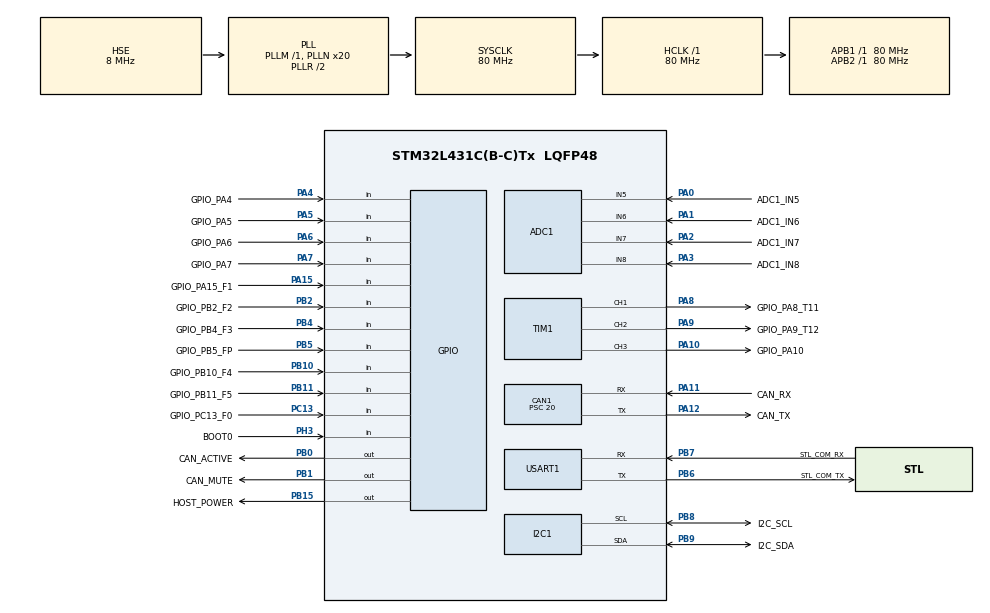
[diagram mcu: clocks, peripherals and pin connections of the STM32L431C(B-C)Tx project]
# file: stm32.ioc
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ADC1.Channel-0\#ChannelRegularConversion=ADC_CHANNEL_5
ADC1.NbrOfConversionFlag=1
ADC1.OffsetNumber-0\#ChannelRegularConversion=ADC_OFFSET_NONE
ADC1.Rank-0\#ChannelRegularConversion=1
ADC1.SamplingTime-0\#ChannelRegularConversion=ADC_SAMPLETIME_2CYCLES_5
ADC1.master=1
CAN1.ABOM=ENABLE
CAN1.BS1=CAN_BS1_13TQ
CAN1.BS2=CAN_BS2_2TQ
CAN1.CalculateBaudRate=250000
CAN1.CalculateTimeBit=4000
CAN1.CalculateTimeQuantum=250.0
CAN1.NART=ENABLE
CAN1.Prescaler=20
CAN1.TXFP=ENABLE
I2C1.Timing=0x10D19CE4
Mcu.Family=STM32L4
Mcu.Name=STM32L431C(B-C)Tx
Mcu.Package=LQFP48
NVIC.CAN1_RX0_IRQn=true\:0\:0\:false\:false\:true\:true\:true\:true
NVIC.CAN1_SCE_IRQn=true\:0\:0\:false\:false\:true\:true\:true\:true
NVIC.CAN1_TX_IRQn=true\:0\:0\:false\:false\:true\:true\:true\:true
NVIC.PriorityGroup=NVIC_PRIORITYGROUP_4
PA0.GPIO_Label=ADC1_IN5
PA0.Signal=ADCx_IN5
PA1.GPIO_Label=ADC1_IN6
PA1.Signal=ADCx_IN6
PA10.GPIO_Label=GPIO_PA10
PA10.Signal=S_TIM1_CH3
PA11.GPIO_Label=CAN_RX
PA11.Mode=CAN_Activate
PA11.Signal=CAN1_RX
PA12.GPIO_Label=CAN_TX
PA12.Mode=CAN_Activate
PA12.Signal=CAN1_TX
PA13\ (JTMS-SWDIO).GPIO_Label=SWDIO
PA13\ (JTMS-SWDIO).Mode=Trace_Asynchronous_SW
PA13\ (JTMS-SWDIO).Signal=SYS_JTMS-SWDIO
PA14\ (JTCK-SWCLK).GPIO_Label=SWCLK
PA14\ (JTCK-SWCLK).Mode=Trace_Asynchronous_SW
PA14\ (JTCK-SWCLK).Signal=SYS_JTCK-SWCLK
PA15\ (JTDI).GPIO_Label=GPIO_PA15_F1
PA15\ (JTDI).Signal=GPIO_Input
PA2.GPIO_Label=ADC1_IN7
PA2.Signal=ADCx_IN7
PA3.GPIO_Label=ADC1_IN8
PA3.Signal=ADCx_IN8
PA4.GPIO_Label=GPIO_PA4
PA4.Signal=GPIO_Input
PA5.GPIO_Label=GPIO_PA5
PA5.Signal=GPIO_Input
PA6.GPIO_Label=GPIO_PA6
PA6.Signal=GPIO_Input
PA7.GPIO_Label=GPIO_PA7
PA7.Signal=GPIO_Input
PA8.GPIO_Label=GPIO_PA8_T11
PA8.Signal=S_TIM1_CH1
PA9.GPIO_Label=GPIO_PA9_T12
PA9.Signal=S_TIM1_CH2
PB0.GPIO_Label=CAN_ACTIVE
PB0.PinState=GPIO_PIN_SET
PB0.Signal=GPIO_Output
PB1.GPIO_Label=CAN_MUTE
PB1.Signal=GPIO_Output
PB10.GPIO_Label=GPIO_PB10_F4
PB10.Signal=GPIO_Input
PB11.GPIO_Label=GPIO_PB11_F5
PB11.Signal=GPIO_Input
PB15.GPIO_Label=HOST_POWER
PB15.Signal=GPIO_Output
PB2.GPIO_Label=GPIO_PB2_F2
PB2.Signal=GPIO_Input
PB3\ (JTDO-TRACESWO).GPIO_Label=TRACESWO
PB3\ (JTDO-TRACESWO).Mode=Trace_Asynchronous_SW
PB3\ (JTDO-TRACESWO).Signal=SYS_JTDO-SWO
PB4\ (NJTRST).GPIO_Label=GPIO_PB4_F3
PB4\ (NJTRST).Signal=GPIO_Input
PB5.GPIO_Label=GPIO_PB5_FP
PB5.Signal=GPIO_Input
PB6.GPIO_Label=STL_COM_TX
PB6.Mode=Asynchronous
PB6.Signal=USART1_TX
PB7.GPIO_Label=STL_COM_RX
PB7.Mode=Asynchronous
PB7.Signal=USART1_RX
PB8.GPIO_Label=I2C_SCL
PB8.Mode=I2C
PB8.Signal=I2C1_SCL
PB9.GPIO_Label=I2C_SDA
PB9.Mode=I2C
PB9.Signal=I2C1_SDA
PC13.GPIO_Label=GPIO_PC13_F0
PC13.Signal=GPIO_Input
PC14-OSC32_IN\ (PC14).Mode=LSE-External-Oscillator
PC14-OSC32_IN\ (PC14).Signal=RCC_OSC32_IN
PC15-OSC32_OUT\ (PC15).Mode=LSE-External-Oscillator
PC15-OSC32_OUT\ (PC15).Signal=RCC_OSC32_OUT
PH0-OSC_IN\ (PH0).Mode=HSE-External-Oscillator
PH0-OSC_IN\ (PH0).Signal=RCC_OSC_IN
PH1-OSC_OUT\ (PH1).Mode=HSE-External-Oscillator
PH1-OSC_OUT\ (PH1).Signal=RCC_OSC_OUT
PH3-BOOT0.GPIO_Label=BOOT0
PH3-BOOT0.Signal=GPIO_Input
ProjectManager.HeapSize=0x200
ProjectManager.StackSize=0x400
ProjectManager.TargetToolchain=CMake
RCC.ADCFreq_Value=32000000
RCC.AHBFreq_Value=80000000
RCC.APB1Freq_Value=80000000
RCC.APB1TimFreq_Value=80000000
RCC.APB2Freq_Value=80000000
RCC.APB2TimFreq_Value=80000000
RCC.CortexFreq_Value=80000000
RCC.HCLKFreq_Value=80000000
RCC.HSI48_VALUE=48000000
RCC.HSI_VALUE=16000000
RCC.MSI_VALUE=4000000
RCC.PLLN=20
RCC.PLLSourceVirtual=RCC_PLLSOURCE_HSE
RCC.RTCClockSelection=RCC_RTCCLKSOURCE_LSE
RCC.SYSCLKFreq_VALUE=80000000
RCC.SYSCLKSource=RCC_SYSCLKSOURCE_PLLCLK
RCC.VCOOutputFreq_Value=160000000
SH.ADCx_IN5.0=ADC1_IN5,IN5-Single-Ended
SH.ADCx_IN6.0=ADC1_IN6,IN6-Single-Ended
SH.ADCx_IN7.0=ADC1_IN7,IN7-Single-Ended
SH.ADCx_IN8.0=ADC1_IN8,IN8-Single-Ended
SH.S_TIM1_CH1.0=TIM1_CH1,PWM Generation1 CH1
SH.S_TIM1_CH2.0=TIM1_CH2,PWM Generation2 CH2
SH.S_TIM1_CH3.0=TIM1_CH3,PWM Generation3 CH3
TIM1.Channel-PWM\ Generation1\ CH1=TIM_CHANNEL_1
TIM1.Channel-PWM\ Generation2\ CH2=TIM_CHANNEL_2
TIM1.Channel-PWM\ Generation3\ CH3=TIM_CHANNEL_3
TIM1.OCPolarity_1=TIM_OCPOLARITY_LOW
TIM1.OCPolarity_2=TIM_OCPOLARITY_LOW
USART1.VirtualMode-Asynchronous=VM_ASYNC
VP_ADC1_Vref_Input.Mode=IN-Vrefint
VP_RTC_VS_RTC_Activate.Mode=RTC_Enabled
board=custom

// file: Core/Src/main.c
/* USER CODE BEGIN Header */
/**
  ******************************************************************************
  * @file           : main.c
  * @brief          : Main program body
  ******************************************************************************
  * @attention
  *
  * Copyright (c) 2026 STMicroelectronics.
  * All rights reserved.
  *
  * This software is licensed under terms that can be found in the LICENSE file
  * in the root directory of this software component.
  * If no LICENSE file comes with this software, it is provided AS-IS.
  *
  ******************************************************************************
  */
/* USER CODE END Header */
#include "main.h"

/* USER CODE BEGIN Includes */
#include "can_mcu/fatal.h"
#include "lab_test_01/app.h"

/* USER CODE END Includes */

ADC_HandleTypeDef hadc1;

CAN_HandleTypeDef hcan1;

I2C_HandleTypeDef hi2c1;

RTC_HandleTypeDef hrtc;

TIM_HandleTypeDef htim1;

UART_HandleTypeDef huart1;

void SystemClock_Config(void);
static void MX_GPIO_Init(void);
static void MX_CAN1_Init(void);
static void MX_I2C1_Init(void);
static void MX_TIM1_Init(void);
static void MX_USART1_UART_Init(void);
static void MX_ADC1_Init(void);
static void MX_RTC_Init(void);

int main(void)
{

  /* MCU Configuration--------------------------------------------------------*/

  /* Reset of all peripherals, Initializes the Flash interface and the Systick. */
  HAL_Init();

  /* Configure the system clock */
  SystemClock_Config();

  /* Initialize all configured peripherals */
  MX_GPIO_Init();
  MX_CAN1_Init();
  MX_I2C1_Init();
  MX_TIM1_Init();
  MX_USART1_UART_Init();
  MX_ADC1_Init();
  MX_RTC_Init();
  /* USER CODE BEGIN 2 */
  lab_test_01_app_init();

  /* USER CODE END 2 */

  /* Infinite loop */
  while (1)
  {

    /* USER CODE BEGIN 3 */
    lab_test_01_app_run();
  }
  /* USER CODE END 3 */
}

void SystemClock_Config(void)
{
  RCC_OscInitTypeDef RCC_OscInitStruct = {0};
  RCC_ClkInitTypeDef RCC_ClkInitStruct = {0};

  /** Configure the main internal regulator output voltage
  */
  if (HAL_PWREx_ControlVoltageScaling(PWR_REGULATOR_VOLTAGE_SCALE1) != HAL_OK)
  {
    Error_Handler();
  }

  /** Configure LSE Drive Capability
  */
  HAL_PWR_EnableBkUpAccess();
  __HAL_RCC_LSEDRIVE_CONFIG(RCC_LSEDRIVE_LOW);

  /** Initializes the RCC Oscillators according to the specified parameters
  * in the RCC_OscInitTypeDef structure.
  */
  RCC_OscInitStruct.OscillatorType = RCC_OSCILLATORTYPE_HSE|RCC_OSCILLATORTYPE_LSE;
  RCC_OscInitStruct.HSEState = RCC_HSE_ON;
  RCC_OscInitStruct.LSEState = RCC_LSE_ON;
  RCC_OscInitStruct.PLL.PLLState = RCC_PLL_ON;
  RCC_OscInitStruct.PLL.PLLSource = RCC_PLLSOURCE_HSE;
  RCC_OscInitStruct.PLL.PLLM = 1;
  RCC_OscInitStruct.PLL.PLLN = 20;
  RCC_OscInitStruct.PLL.PLLP = RCC_PLLP_DIV7;
  RCC_OscInitStruct.PLL.PLLQ = RCC_PLLQ_DIV2;
  RCC_OscInitStruct.PLL.PLLR = RCC_PLLR_DIV2;
  if (HAL_RCC_OscConfig(&RCC_OscInitStruct) != HAL_OK)
  {
    Error_Handler();
  }

  /** Initializes the CPU, AHB and APB buses clocks
  */
  RCC_ClkInitStruct.ClockType = RCC_CLOCKTYPE_HCLK|RCC_CLOCKTYPE_SYSCLK
                              |RCC_CLOCKTYPE_PCLK1|RCC_CLOCKTYPE_PCLK2;
  RCC_ClkInitStruct.SYSCLKSource = RCC_SYSCLKSOURCE_PLLCLK;
  RCC_ClkInitStruct.AHBCLKDivider = RCC_SYSCLK_DIV1;
  RCC_ClkInitStruct.APB1CLKDivider = RCC_HCLK_DIV1;
  RCC_ClkInitStruct.APB2CLKDivider = RCC_HCLK_DIV1;

  if (HAL_RCC_ClockConfig(&RCC_ClkInitStruct, FLASH_LATENCY_4) != HAL_OK)
  {
    Error_Handler();
  }
}

static void MX_ADC1_Init(void)
{

  ADC_ChannelConfTypeDef sConfig = {0};

  /** Common config
  */
  hadc1.Instance = ADC1;
  hadc1.Init.ClockPrescaler = ADC_CLOCK_ASYNC_DIV1;
  hadc1.Init.Resolution = ADC_RESOLUTION_12B;
  hadc1.Init.DataAlign = ADC_DATAALIGN_RIGHT;
  hadc1.Init.ScanConvMode = ADC_SCAN_DISABLE;
  hadc1.Init.EOCSelection = ADC_EOC_SINGLE_CONV;
  hadc1.Init.LowPowerAutoWait = DISABLE;
  hadc1.Init.ContinuousConvMode = DISABLE;
  hadc1.Init.NbrOfConversion = 1;
  hadc1.Init.DiscontinuousConvMode = DISABLE;
  hadc1.Init.ExternalTrigConv = ADC_SOFTWARE_START;
  hadc1.Init.ExternalTrigConvEdge = ADC_EXTERNALTRIGCONVEDGE_NONE;
  hadc1.Init.DMAContinuousRequests = DISABLE;
  hadc1.Init.Overrun = ADC_OVR_DATA_PRESERVED;
  hadc1.Init.OversamplingMode = DISABLE;
  if (HAL_ADC_Init(&hadc1) != HAL_OK)
  {
    Error_Handler();
  }

  /** Configure Regular Channel
  */
  sConfig.Channel = ADC_CHANNEL_5;
  sConfig.Rank = ADC_REGULAR_RANK_1;
  sConfig.SamplingTime = ADC_SAMPLETIME_2CYCLES_5;
  sConfig.SingleDiff = ADC_SINGLE_ENDED;
  sConfig.OffsetNumber = ADC_OFFSET_NONE;
  sConfig.Offset = 0;
  if (HAL_ADC_ConfigChannel(&hadc1, &sConfig) != HAL_OK)
  {
    Error_Handler();
  }

}

static void MX_CAN1_Init(void)
{

  hcan1.Instance = CAN1;
  hcan1.Init.Prescaler = 20;
  hcan1.Init.Mode = CAN_MODE_NORMAL;
  hcan1.Init.SyncJumpWidth = CAN_SJW_1TQ;
  hcan1.Init.TimeSeg1 = CAN_BS1_13TQ;
  hcan1.Init.TimeSeg2 = CAN_BS2_2TQ;
  hcan1.Init.TimeTriggeredMode = DISABLE;
  hcan1.Init.AutoBusOff = ENABLE;
  hcan1.Init.AutoWakeUp = DISABLE;
  hcan1.Init.AutoRetransmission = ENABLE;
  hcan1.Init.ReceiveFifoLocked = DISABLE;
  hcan1.Init.TransmitFifoPriority = ENABLE;
  if (HAL_CAN_Init(&hcan1) != HAL_OK)
  {
    Error_Handler();
  }

}

static void MX_I2C1_Init(void)
{

  hi2c1.Instance = I2C1;
  hi2c1.Init.Timing = 0x10D19CE4;
  hi2c1.Init.OwnAddress1 = 0;
  hi2c1.Init.AddressingMode = I2C_ADDRESSINGMODE_7BIT;
  hi2c1.Init.DualAddressMode = I2C_DUALADDRESS_DISABLE;
  hi2c1.Init.OwnAddress2 = 0;
  hi2c1.Init.OwnAddress2Masks = I2C_OA2_NOMASK;
  hi2c1.Init.GeneralCallMode = I2C_GENERALCALL_DISABLE;
  hi2c1.Init.NoStretchMode = I2C_NOSTRETCH_DISABLE;
  if (HAL_I2C_Init(&hi2c1) != HAL_OK)
  {
    Error_Handler();
  }

  /** Configure Analogue filter
  */
  if (HAL_I2CEx_ConfigAnalogFilter(&hi2c1, I2C_ANALOGFILTER_ENABLE) != HAL_OK)
  {
    Error_Handler();
  }

  /** Configure Digital filter
  */
  if (HAL_I2CEx_ConfigDigitalFilter(&hi2c1, 0) != HAL_OK)
  {
    Error_Handler();
  }

}

static void MX_RTC_Init(void)
{

  /** Initialize RTC Only
  */
  hrtc.Instance = RTC;
  hrtc.Init.HourFormat = RTC_HOURFORMAT_24;
  hrtc.Init.AsynchPrediv = 127;
  hrtc.Init.SynchPrediv = 255;
  hrtc.Init.OutPut = RTC_OUTPUT_DISABLE;
  hrtc.Init.OutPutRemap = RTC_OUTPUT_REMAP_NONE;
  hrtc.Init.OutPutPolarity = RTC_OUTPUT_POLARITY_HIGH;
  hrtc.Init.OutPutType = RTC_OUTPUT_TYPE_OPENDRAIN;
  if (HAL_RTC_Init(&hrtc) != HAL_OK)
  {
    Error_Handler();
  }

}

static void MX_TIM1_Init(void)
{

  TIM_MasterConfigTypeDef sMasterConfig = {0};
  TIM_OC_InitTypeDef sConfigOC = {0};
  TIM_BreakDeadTimeConfigTypeDef sBreakDeadTimeConfig = {0};

  htim1.Instance = TIM1;
  htim1.Init.Prescaler = 0;
  htim1.Init.CounterMode = TIM_COUNTERMODE_UP;
  htim1.Init.Period = 65535;
  htim1.Init.ClockDivision = TIM_CLOCKDIVISION_DIV1;
  htim1.Init.RepetitionCounter = 0;
  htim1.Init.AutoReloadPreload = TIM_AUTORELOAD_PRELOAD_DISABLE;
  if (HAL_TIM_PWM_Init(&htim1) != HAL_OK)
  {
    Error_Handler();
  }
  sMasterConfig.MasterOutputTrigger = TIM_TRGO_RESET;
  sMasterConfig.MasterOutputTrigger2 = TIM_TRGO2_RESET;
  sMasterConfig.MasterSlaveMode = TIM_MASTERSLAVEMODE_DISABLE;
  if (HAL_TIMEx_MasterConfigSynchronization(&htim1, &sMasterConfig) != HAL_OK)
  {
    Error_Handler();
  }
  sConfigOC.OCMode = TIM_OCMODE_PWM1;
  sConfigOC.Pulse = 0;
  sConfigOC.OCPolarity = TIM_OCPOLARITY_LOW;
  sConfigOC.OCNPolarity = TIM_OCNPOLARITY_HIGH;
  sConfigOC.OCFastMode = TIM_OCFAST_DISABLE;
  sConfigOC.OCIdleState = TIM_OCIDLESTATE_RESET;
  sConfigOC.OCNIdleState = TIM_OCNIDLESTATE_RESET;
  if (HAL_TIM_PWM_ConfigChannel(&htim1, &sConfigOC, TIM_CHANNEL_1) != HAL_OK)
  {
    Error_Handler();
  }
  if (HAL_TIM_PWM_ConfigChannel(&htim1, &sConfigOC, TIM_CHANNEL_2) != HAL_OK)
  {
    Error_Handler();
  }
  sConfigOC.OCPolarity = TIM_OCPOLARITY_HIGH;
  if (HAL_TIM_PWM_ConfigChannel(&htim1, &sConfigOC, TIM_CHANNEL_3) != HAL_OK)
  {
    Error_Handler();
  }
  sBreakDeadTimeConfig.OffStateRunMode = TIM_OSSR_DISABLE;
  sBreakDeadTimeConfig.OffStateIDLEMode = TIM_OSSI_DISABLE;
  sBreakDeadTimeConfig.LockLevel = TIM_LOCKLEVEL_OFF;
  sBreakDeadTimeConfig.DeadTime = 0;
  sBreakDeadTimeConfig.BreakState = TIM_BREAK_DISABLE;
  sBreakDeadTimeConfig.BreakPolarity = TIM_BREAKPOLARITY_HIGH;
  sBreakDeadTimeConfig.BreakFilter = 0;
  sBreakDeadTimeConfig.Break2State = TIM_BREAK2_DISABLE;
  sBreakDeadTimeConfig.Break2Polarity = TIM_BREAK2POLARITY_HIGH;
  sBreakDeadTimeConfig.Break2Filter = 0;
  sBreakDeadTimeConfig.AutomaticOutput = TIM_AUTOMATICOUTPUT_DISABLE;
  if (HAL_TIMEx_ConfigBreakDeadTime(&htim1, &sBreakDeadTimeConfig) != HAL_OK)
  {
    Error_Handler();
  }
  HAL_TIM_MspPostInit(&htim1);

}

static void MX_USART1_UART_Init(void)
{

  huart1.Instance = USART1;
  huart1.Init.BaudRate = 115200;
  huart1.Init.WordLength = UART_WORDLENGTH_8B;
  huart1.Init.StopBits = UART_STOPBITS_1;
  huart1.Init.Parity = UART_PARITY_NONE;
  huart1.Init.Mode = UART_MODE_TX_RX;
  huart1.Init.HwFlowCtl = UART_HWCONTROL_NONE;
  huart1.Init.OverSampling = UART_OVERSAMPLING_16;
  huart1.Init.OneBitSampling = UART_ONE_BIT_SAMPLE_DISABLE;
  huart1.AdvancedInit.AdvFeatureInit = UART_ADVFEATURE_NO_INIT;
  if (HAL_UART_Init(&huart1) != HAL_OK)
  {
    Error_Handler();
  }

}

static void MX_GPIO_Init(void)
{
  GPIO_InitTypeDef GPIO_InitStruct = {0};

  /* GPIO Ports Clock Enable */
  __HAL_RCC_GPIOC_CLK_ENABLE();
  __HAL_RCC_GPIOH_CLK_ENABLE();
  __HAL_RCC_GPIOA_CLK_ENABLE();
  __HAL_RCC_GPIOB_CLK_ENABLE();

  /*Configure GPIO pin Output Level */
  HAL_GPIO_WritePin(CAN_ACTIVE_GPIO_Port, CAN_ACTIVE_Pin, GPIO_PIN_SET);

  /*Configure GPIO pin Output Level */
  HAL_GPIO_WritePin(GPIOB, CAN_MUTE_Pin|HOST_POWER_Pin, GPIO_PIN_RESET);

  /*Configure GPIO pin : GPIO_PC13_F0_Pin */
  GPIO_InitStruct.Pin = GPIO_PC13_F0_Pin;
  GPIO_InitStruct.Mode = GPIO_MODE_INPUT;
  GPIO_InitStruct.Pull = GPIO_NOPULL;
  HAL_GPIO_Init(GPIO_PC13_F0_GPIO_Port, &GPIO_InitStruct);

  /*Configure GPIO pins : GPIO_PA4_Pin GPIO_PA5_Pin GPIO_PA6_Pin GPIO_PA7_Pin
                           GPIO_PA15_F1_Pin */
  GPIO_InitStruct.Pin = GPIO_PA4_Pin|GPIO_PA5_Pin|GPIO_PA6_Pin|GPIO_PA7_Pin
                          |GPIO_PA15_F1_Pin;
  GPIO_InitStruct.Mode = GPIO_MODE_INPUT;
  GPIO_InitStruct.Pull = GPIO_NOPULL;
  HAL_GPIO_Init(GPIOA, &GPIO_InitStruct);

  /*Configure GPIO pins : CAN_ACTIVE_Pin CAN_MUTE_Pin HOST_POWER_Pin */
  GPIO_InitStruct.Pin = CAN_ACTIVE_Pin|CAN_MUTE_Pin|HOST_POWER_Pin;
  GPIO_InitStruct.Mode = GPIO_MODE_OUTPUT_PP;
  GPIO_InitStruct.Pull = GPIO_NOPULL;
  GPIO_InitStruct.Speed = GPIO_SPEED_FREQ_LOW;
  HAL_GPIO_Init(GPIOB, &GPIO_InitStruct);

  /*Configure GPIO pins : GPIO_PB2_F2_Pin GPIO_PB10_F4_Pin GPIO_PB11_F5_Pin GPIO_PB4_F3_Pin
                           GPIO_PB5_FP_Pin */
  GPIO_InitStruct.Pin = GPIO_PB2_F2_Pin|GPIO_PB10_F4_Pin|GPIO_PB11_F5_Pin|GPIO_PB4_F3_Pin
                          |GPIO_PB5_FP_Pin;
  GPIO_InitStruct.Mode = GPIO_MODE_INPUT;
  GPIO_InitStruct.Pull = GPIO_NOPULL;
  HAL_GPIO_Init(GPIOB, &GPIO_InitStruct);

  /*Configure GPIO pin : BOOT0_Pin */
  GPIO_InitStruct.Pin = BOOT0_Pin;
  GPIO_InitStruct.Mode = GPIO_MODE_INPUT;
  GPIO_InitStruct.Pull = GPIO_NOPULL;
  HAL_GPIO_Init(BOOT0_GPIO_Port, &GPIO_InitStruct);

}

void Error_Handler(void)
{
  /* USER CODE BEGIN Error_Handler_Debug */
  can_mcu_fatal_error("Error_Handler");
  /* USER CODE END Error_Handler_Debug */
}
